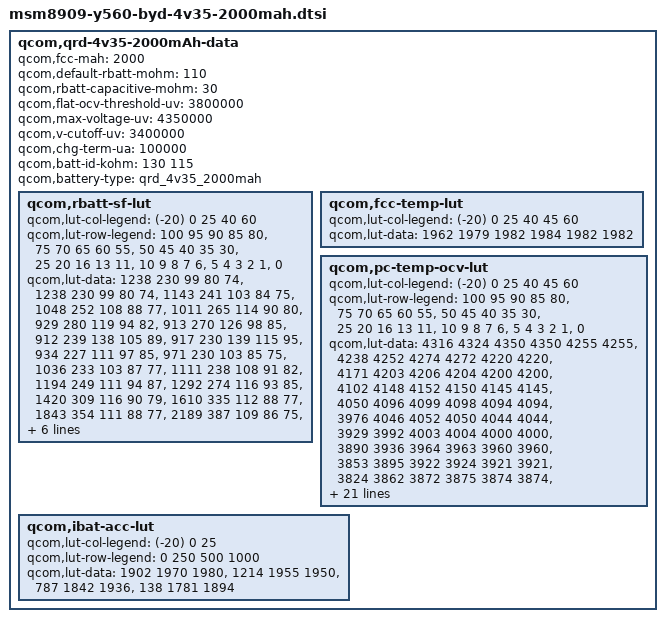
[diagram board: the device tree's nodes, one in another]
/* Copyright (c) 2013, The Linux Foundation. All rights reserved.
 *
 * This program is free software; you can redistribute it and/or modify
 * it under the terms of the GNU General Public License version 2 and
 * only version 2 as published by the Free Software Foundation.
 *
 * This program is distributed in the hope that it will be useful,
 * but WITHOUT ANY WARRANTY; without even the implied warranty of
 * MERCHANTABILITY or FITNESS FOR A PARTICULAR PURPOSE.  See the
 * GNU General Public License for more details.
 */
/* xiongzuan add battery information capacity and rbatt by 20150520 begin*/
qcom,qrd-4v35-2000mAh-data {
	qcom,fcc-mah = <2000>;
	qcom,default-rbatt-mohm = <110>;
	qcom,rbatt-capacitive-mohm = <30>;
	qcom,flat-ocv-threshold-uv = <3800000>;
	qcom,max-voltage-uv = <4350000>;
	qcom,v-cutoff-uv = <3400000>;
	qcom,chg-term-ua = <100000>;
	qcom,batt-id-kohm = <130 115>;
	qcom,battery-type = "qrd_4v35_2000mah";

	qcom,rbatt-sf-lut {
		qcom,lut-col-legend = <(-20) 0 25 40 60>;
		qcom,lut-row-legend = <100 95 90 85 80>,
				<75 70 65 60 55>,
				<50 45 40 35 30>,
				<25 20 16 13 11>,
				<10 9 8 7 6 >,
				<5 4 3 2 1>,
				<0>;
		qcom,lut-data = 
				<1238 230 99 80 74>,
				<1238 230 99 80 74>,
				<1143 241 103 84 75>,
				<1048 252 108 88 77>,
				<1011 265 114 90 80>,
				<929 280 119 94 82>,
				<913 270 126 98 85>,
				<912 239 138 105 89>,
				<917 230 139 115 95>,
				<934 227 111 97 85>,
				<971 230 103 85 75>,
				<1036 233 103 87 77>,
				<1111 238 108 91 82>,
				<1194 249 111 94 87>,
				<1292 274 116 93 85>,
				<1420 309 116 90 79>,
				<1610 335 112 88 77>,
				<1843 354 111 88 77>,
				<2189 387 109 86 75>,
				<2650 428 111 89 79>,
				<2770 449 115 92 80>,//10
				<2985 488 119 94 80>,
				<3418 524 123 96 83>,
				<3638 519 130 98 84>,
				<4565 587 134 98 84>,
				<6066 620 126 98 82>,
				<9075 605 131 98 84>,
				<8149 640 130 107 89>,
				<6298 631 132 123 100>,
				<7259 662 129 121 123>,
				<9451 925 257 243 207>;
	};

	qcom,fcc-temp-lut {
		qcom,lut-col-legend = <(-20) 0 25 40 45 60>;
		qcom,lut-data = <1962 1979 1982 1984 1982 1982>;
	};

	qcom,pc-temp-ocv-lut {
		qcom,lut-col-legend = <(-20) 0 25 40 45 60>;
		qcom,lut-row-legend = <100 95 90 85 80>,
				<75 70 65 60 55>,
				<50 45 40 35 30>,
				<25 20 16 13 11>,
				<10 9 8 7 6>,
				<5 4 3 2 1>,
				<0>;
		qcom,lut-data = 
 				<4316 4324 4350 4350 4255 4255>,//100
				<4238 4252 4274 4272 4220 4220>,
				<4171 4203 4206 4204 4200 4200>,//90
				<4102 4148 4152 4150 4145 4145>,
				<4050 4096 4099 4098 4094 4094>,//80
				<3976 4046 4052 4050 4044 4044>,
				<3929 3992 4003 4004 4000 4000>,//70
				<3890 3936 3964 3963 3960 3960>,
				<3853 3895 3922 3924 3921 3921>,//60
				<3824 3862 3872 3875 3874 3874>,
				<3804 3834 3839 3839 3838 3838>,//50
				<3786 3811 3818 3817 3814 3814>,
				<3769 3792 3799 3798 3794 3794>,//40
				<3752 3780 3785 3783 3779 3779>,
				<3737 3772 3770 3766 3761 3761>,//30
				<3724 3760 3758 3750 3737 3737>,
				<3710 3738 3738 3728 3715 3715>,//20
				<3698 3712 3709 3700 3688 3688>,
				<3685 3694 3686 3678 3666 3676>,//13
				<3668 3686 3680 3674 3662 3668>,
				<3660 3684 3679 3672 3660 3660>,//10
				<3645 3681 3677 3670 3658 3658>,
				<3628 3677 3675 3668 3656 3656>,
				<3606 3672 3670 3664 3651 3651>,
				<3576 3663 3662 3652 3638 3638>,
				<3535 3644 3637 3624 3604 3604>,
				<3478 3604 3589 3574 3552 3552>,
				<3398 3544 3522 3506 3490 3490>,
				<3360 3459 3432 3422 3398 3398>,
				<3340 3327 3390 3381 3354 3354>,
				<3300 3300 3300 3300 3300 3300>; 
	};
	qcom,ibat-acc-lut {
		qcom,lut-col-legend = <(-20) 0 25>;
		qcom,lut-row-legend = <0 250 500 1000>;
		qcom,lut-data = 
				<1902 1970 1980>,
				<1214 1955 1950>,
				<787 1842 1936>,
				<138 1781 1894>;
	};
};
/* xiongzuan add battery information capacity and rbatt by 20150520 end*/
